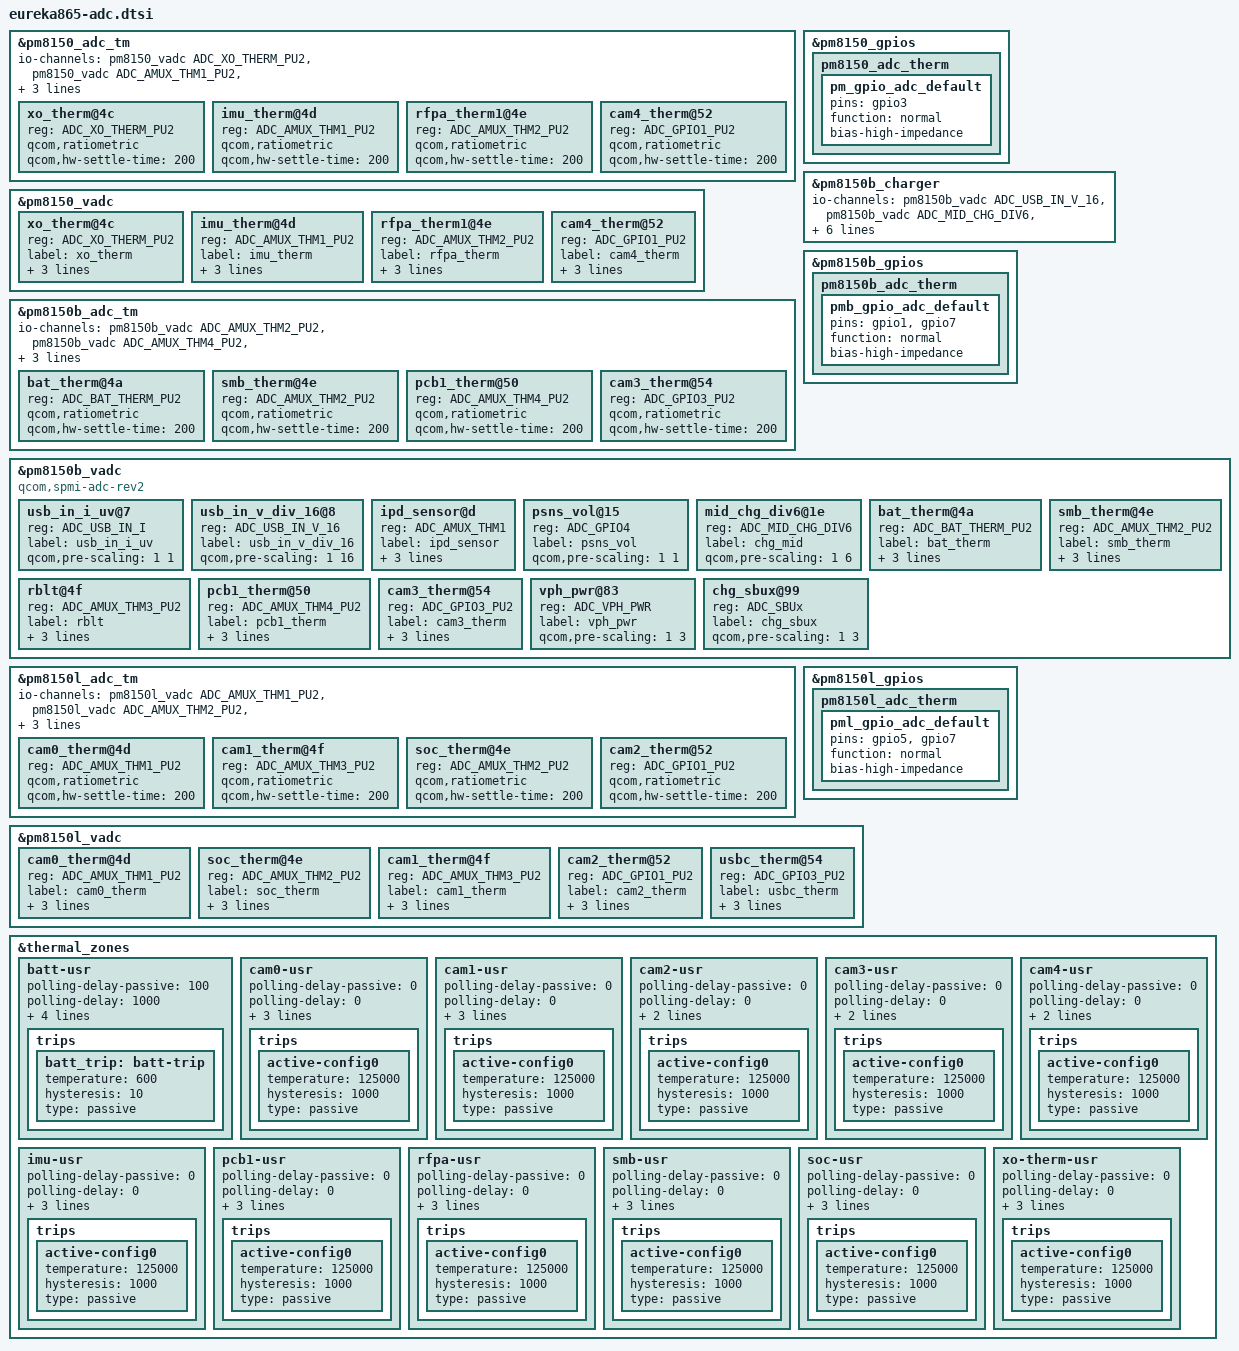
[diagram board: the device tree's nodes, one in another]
// SPDX-License-Identifier: GPL-2.0

&pm8150_adc_tm {
	#address-cells = <1>;
	#size-cells = <0>;

	io-channels = <&pm8150_vadc ADC_XO_THERM_PU2>,
		<&pm8150_vadc ADC_AMUX_THM1_PU2>,
		<&pm8150_vadc ADC_AMUX_THM2_PU2>,
		<&pm8150_vadc ADC_GPIO1_PU2>;

	pinctrl-names = "default";
	pinctrl-0 = <&pm_gpio_adc_default>;

	xo_therm@4c {
		reg = <ADC_XO_THERM_PU2>;
		qcom,ratiometric;
		qcom,hw-settle-time = <200>;
	};

	imu_therm@4d {
		reg = <ADC_AMUX_THM1_PU2>;
		qcom,ratiometric;
		qcom,hw-settle-time = <200>;
	};

	rfpa_therm1@4e {
		reg = <ADC_AMUX_THM2_PU2>;
		qcom,ratiometric;
		qcom,hw-settle-time = <200>;
	};

	cam4_therm@52 {
		/* RGB camera */
		reg = <ADC_GPIO1_PU2>;
		qcom,ratiometric;
		qcom,hw-settle-time = <200>;
	};
};

&pm8150_gpios {
	pm8150_adc_therm {
		pm_gpio_adc_default: pm_gpio_adc_default {
			pins = "gpio3";
			function = "normal";
			bias-high-impedance;
		};
	};
};

&pm8150_vadc {
	#address-cells = <1>;
	#size-cells = <0>;

	xo_therm@4c {
		reg = <ADC_XO_THERM_PU2>;
		label = "xo_therm";
		qcom,ratiometric;
		qcom,hw-settle-time = <200>;
		qcom,pre-scaling = <1 1>;
	};

	imu_therm@4d {
		reg = <ADC_AMUX_THM1_PU2>;
		label = "imu_therm";
		qcom,ratiometric;
		qcom,hw-settle-time = <200>;
		qcom,pre-scaling = <1 1>;
	};

	rfpa_therm1@4e {
		reg = <ADC_AMUX_THM2_PU2>;
		label = "rfpa_therm";
		qcom,ratiometric;
		qcom,hw-settle-time = <200>;
		qcom,pre-scaling = <1 1>;
	};

	cam4_therm@52 {
		/* RGB camera */
		reg = <ADC_GPIO1_PU2>;
		label = "cam4_therm";
		qcom,ratiometric;
		qcom,hw-settle-time = <200>;
		qcom,pre-scaling = <1 1>;
	};
};

&pm8150b_adc_tm {
	#address-cells = <1>;
	#size-cells = <0>;

	io-channels = <&pm8150b_vadc ADC_AMUX_THM2_PU2>,
		<&pm8150b_vadc ADC_AMUX_THM4_PU2>,
		<&pm8150b_vadc ADC_BAT_THERM_PU2>,
		<&pm8150b_vadc ADC_GPIO3_PU2>;

	pinctrl-names = "default";
	pinctrl-0 = <&pmb_gpio_adc_default>;

	bat_therm@4a {
		reg = <ADC_BAT_THERM_PU2>;
		qcom,ratiometric;
		qcom,hw-settle-time = <200>;
	};

	smb_therm@4e {
		reg = <ADC_AMUX_THM2_PU2>;
		qcom,ratiometric;
		qcom,hw-settle-time = <200>;
	};

	pcb1_therm@50 {
		reg = <ADC_AMUX_THM4_PU2>;
		qcom,ratiometric;
		qcom,hw-settle-time = <200>;
	};

	cam3_therm@54 {
		/* Canyon right */
		reg = <ADC_GPIO3_PU2>;
		qcom,ratiometric;
		qcom,hw-settle-time = <200>;
	};
};

&pm8150b_charger {
	io-channels = <&pm8150b_vadc ADC_USB_IN_V_16>,
		      <&pm8150b_vadc ADC_MID_CHG_DIV6>,
		      <&pm8150b_vadc ADC_USB_IN_I>,
		      <&pm8150b_vadc ADC_SBUx>,
		      <&pm8150b_vadc ADC_VPH_PWR>,
		      <&pm8150b_vadc ADC_CHG_TEMP>,
		      <&pm8150b_vadc ADC_AMUX_THM3_PU2>,
		      <&pm8150b_vadc ADC_GPIO4>;
	io-channel-names = "usb_in_voltage",
			   "mid_voltage",
			   "usb_in_current",
			   "sbux_res",
			   "vph_voltage",
			   "chg_temp",
			   "rblt_res",
			   "psns_res";
};

&pm8150b_gpios {
	pm8150b_adc_therm {
		pmb_gpio_adc_default: pmb_gpio_adc_default {
			pins = "gpio1", "gpio7";
			function = "normal";
			bias-high-impedance;
		};
	};
};

&pm8150b_vadc {
	#address-cells = <1>;
	#size-cells = <0>;
	compatible = "qcom,spmi-adc-rev2";

	usb_in_i_uv@7 {
		reg = <ADC_USB_IN_I>;
		label = "usb_in_i_uv";
		qcom,pre-scaling = <1 1>;
	};

	usb_in_v_div_16@8 {
		reg = <ADC_USB_IN_V_16>;
		label = "usb_in_v_div_16";
		qcom,pre-scaling = <1 16>;
	};

	ipd_sensor@d {
		reg = <ADC_AMUX_THM1>;
		label = "ipd_sensor";
		qcom,hw-settle-time = <200>;
		qcom,pre-scaling = <1 1>;
		qcom,decimation = <1024>;
	};

	psns_vol@15 {
		reg = <ADC_GPIO4>;
		label = "psns_vol";
		qcom,pre-scaling = <1 1>;
	};

	mid_chg_div6@1e {
		reg = <ADC_MID_CHG_DIV6>;
		label = "chg_mid";
		qcom,pre-scaling = <1 6>;
	};

	bat_therm@4a {
		reg = <ADC_BAT_THERM_PU2>;
		label = "bat_therm";
		qcom,ratiometric;
		qcom,hw-settle-time = <200>;
		qcom,pre-scaling = <1 1>;
	};

	smb_therm@4e {
		reg = <ADC_AMUX_THM2_PU2>;
		label = "smb_therm";
		qcom,ratiometric;
		qcom,hw-settle-time = <200>;
		qcom,pre-scaling = <1 1>;
	};

	rblt@4f {
		reg = <ADC_AMUX_THM3_PU2>;
		label = "rblt";
		qcom,ratiometric;
		qcom,hw-settle-time = <200>;
		qcom,pre-scaling = <1 1>;
	};

	pcb1_therm@50 {
		reg = <ADC_AMUX_THM4_PU2>;
		label = "pcb1_therm";
		qcom,ratiometric;
		qcom,hw-settle-time = <200>;
		qcom,pre-scaling = <1 1>;
	};

	cam3_therm@54 {
		/* Canyon right */
		reg = <ADC_GPIO3_PU2>;
		label = "cam3_therm";
		qcom,ratiometric;
		qcom,hw-settle-time = <200>;
		qcom,pre-scaling = <1 1>;
	};

	vph_pwr@83 {
		reg = <ADC_VPH_PWR>;
		label = "vph_pwr";
		qcom,pre-scaling = <1 3>;
	};

	chg_sbux@99 {
		reg = <ADC_SBUx>;
		label = "chg_sbux";
		qcom,pre-scaling = <1 3>;
	};
};

&pm8150l_adc_tm {
	#address-cells = <1>;
	#size-cells = <0>;

	/* TODO: T97956664 fix the missed USB-C thermistor in P1 */
	io-channels = <&pm8150l_vadc ADC_AMUX_THM1_PU2>,
		<&pm8150l_vadc ADC_AMUX_THM2_PU2>,
		<&pm8150l_vadc ADC_AMUX_THM3_PU2>,
		<&pm8150l_vadc ADC_GPIO1_PU2>;

	pinctrl-names = "default";
	pinctrl-0 = <&pml_gpio_adc_default>;

	cam0_therm@4d {
		/* Glacier left */
		reg = <ADC_AMUX_THM1_PU2>;
		qcom,ratiometric;
		qcom,hw-settle-time = <200>;
	};

	cam1_therm@4f {
		/* Glacier right */
		reg = <ADC_AMUX_THM3_PU2>;
		qcom,ratiometric;
		qcom,hw-settle-time = <200>;
	};

	soc_therm@4e {
		reg = <ADC_AMUX_THM2_PU2>;
		qcom,ratiometric;
		qcom,hw-settle-time = <200>;
	};

	cam2_therm@52 {
		/* Canyon left */
		reg = <ADC_GPIO1_PU2>;
		qcom,ratiometric;
		qcom,hw-settle-time = <200>;
	};
};

&pm8150l_gpios {
	pm8150l_adc_therm {
		pml_gpio_adc_default: pml_gpio_adc_default {
			pins = "gpio5", "gpio7";
			function = "normal";
			bias-high-impedance;
		};
	};
};

&pm8150l_vadc {
	#address-cells = <1>;
	#size-cells = <0>;

	cam0_therm@4d {
		/* Glacier left */
		reg = <ADC_AMUX_THM1_PU2>;
		label = "cam0_therm";
		qcom,ratiometric;
		qcom,hw-settle-time = <200>;
		qcom,pre-scaling = <1 1>;
	};

	soc_therm@4e {
		reg = <ADC_AMUX_THM2_PU2>;
		label = "soc_therm";
		qcom,ratiometric;
		qcom,hw-settle-time = <200>;
		qcom,pre-scaling = <1 1>;
	};

	cam1_therm@4f {
		/* Glacier right */
		reg = <ADC_AMUX_THM3_PU2>;
		label = "cam1_therm";
		qcom,ratiometric;
		qcom,hw-settle-time = <200>;
		qcom,pre-scaling = <1 1>;
	};

	cam2_therm@52 {
		/* Canyon left */
		reg = <ADC_GPIO1_PU2>;
		label = "cam2_therm";
		qcom,ratiometric;
		qcom,hw-settle-time = <200>;
		qcom,pre-scaling = <1 1>;
	};

	usbc_therm@54 {
		reg = <ADC_GPIO3_PU2>;
		label = "usbc_therm";
		qcom,ratiometric;
		qcom,hw-settle-time = <200>;
		qcom,pre-scaling = <1 1>;
	};
};

&thermal_zones {
	batt-usr {
		polling-delay-passive = <100>;
		polling-delay = <1000>;
		thermal-governor = "user_space";
		thermal-sensors = <&pm8150b_adc_tm ADC_BAT_THERM_PU2>;
		wake-capable-sensor;
		trips {
			batt_trip: batt-trip {
				temperature = <600>;
				hysteresis = <10>;
				type = "passive";
			};
		};
	};

	cam0-usr {
		/* Glacier left */
		polling-delay-passive = <0>;
		polling-delay = <0>;
		thermal-governor = "user_space";
		thermal-sensors = <&pm8150l_adc_tm ADC_AMUX_THM1_PU2>;
		trips {
			active-config0 {
				temperature = <125000>;
				hysteresis = <1000>;
				type = "passive";
			};
		};
	};

	cam1-usr {
		/* Glacier right */
		polling-delay-passive = <0>;
		polling-delay = <0>;
		thermal-governor = "user_space";
		thermal-sensors = <&pm8150l_adc_tm ADC_AMUX_THM3_PU2>;
		trips {
			active-config0 {
				temperature = <125000>;
				hysteresis = <1000>;
				type = "passive";
			};
		};
	};

	cam2-usr {
		/* Canyon left */
		polling-delay-passive = <0>;
		polling-delay = <0>;
		thermal-governor = "user_space";
		thermal-sensors = <&pm8150l_adc_tm ADC_GPIO1_PU2>;
		trips {
			active-config0 {
				temperature = <125000>;
				hysteresis = <1000>;
				type = "passive";
			};
		};
	};

	cam3-usr {
		/* Canyon right */
		polling-delay-passive = <0>;
		polling-delay = <0>;
		thermal-governor = "user_space";
		thermal-sensors = <&pm8150b_adc_tm ADC_GPIO3_PU2>;
		trips {
			active-config0 {
				temperature = <125000>;
				hysteresis = <1000>;
				type = "passive";
			};
		};
	};

	cam4-usr {
		/* RGB camera */
		polling-delay-passive = <0>;
		polling-delay = <0>;
		thermal-governor = "user_space";
		thermal-sensors = <&pm8150_adc_tm ADC_GPIO1_PU2>;
		trips {
			active-config0 {
				temperature = <125000>;
				hysteresis = <1000>;
				type = "passive";
			};
		};
	};

	imu-usr {
		polling-delay-passive = <0>;
		polling-delay = <0>;
		thermal-governor = "user_space";
		thermal-sensors = <&pm8150_adc_tm ADC_AMUX_THM1_PU2>;
		trips {
			active-config0 {
				temperature = <125000>;
				hysteresis = <1000>;
				type = "passive";
			};
		};
	};

	pcb1-usr {
		polling-delay-passive = <0>;
		polling-delay = <0>;
		thermal-governor = "user_space";
		thermal-sensors = <&pm8150b_adc_tm ADC_AMUX_THM4_PU2>;
		trips {
			active-config0 {
				temperature = <125000>;
				hysteresis = <1000>;
				type = "passive";
			};
		};
	};

	rfpa-usr {
		polling-delay-passive = <0>;
		polling-delay = <0>;
		thermal-governor = "user_space";
		thermal-sensors = <&pm8150_adc_tm ADC_AMUX_THM2_PU2>;
		trips {
			active-config0 {
				temperature = <125000>;
				hysteresis = <1000>;
				type = "passive";
			};
		};
	};

	smb-usr {
		polling-delay-passive = <0>;
		polling-delay = <0>;
		thermal-governor = "user_space";
		thermal-sensors = <&pm8150b_adc_tm ADC_AMUX_THM2_PU2>;
		trips {
			active-config0 {
				temperature = <125000>;
				hysteresis = <1000>;
				type = "passive";
			};
		};
	};

	soc-usr {
		polling-delay-passive = <0>;
		polling-delay = <0>;
		thermal-governor = "user_space";
		thermal-sensors = <&pm8150l_adc_tm ADC_AMUX_THM2_PU2>;
		trips {
			active-config0 {
				temperature = <125000>;
				hysteresis = <1000>;
				type = "passive";
			};
		};
	};

	xo-therm-usr {
		polling-delay-passive = <0>;
		polling-delay = <0>;
		thermal-governor = "user_space";
		thermal-sensors = <&pm8150_adc_tm ADC_XO_THERM_PU2>;
		trips {
			active-config0 {
				temperature = <125000>;
				hysteresis = <1000>;
				type = "passive";
			};
		};
	};
};
